AUTOSAR XML (schema 4-3-0)
package /ApplicationLayer/ApplicationPackage
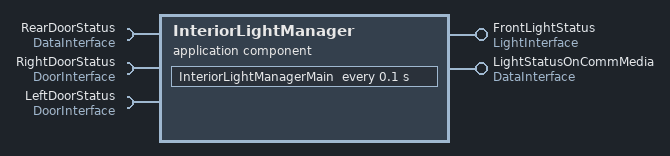
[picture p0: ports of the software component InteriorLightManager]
  application sw component type InteriorLightManager
    require port RearDoorStatus: required-interface=DataInterface
    require port RightDoorStatus: required-interface=DoorInterface
    require port LeftDoorStatus: required-interface=DoorInterface
    provide port FrontLightStatus: provided-interface=LightInterface
    provide port LightStatusOnCommMedia: provided-interface=DataInterface
    behavior InteriorLightManagerBehaviour: data-type-mapping=TypeMappings, handle-termination-and-restart=NO-SUPPORT
      timing event interiorLightManagerMainEvent: start-on-event=InteriorLightManagerMain, period=0.1
      runnable InteriorLightManagerMain: symbol=interiorLightManagerMain
        data-read-access:
          access dataReadAccess_InteriorLightManagerMain_RearDoorStatus_message: accessed-variable=RearDoorStatus.message
          access dataReadAccess_InteriorLightManagerMain_RightDoorStatus_status: accessed-variable=RightDoorStatus.status
          access dataReadAccess_InteriorLightManagerMain_LeftDoorStatus_status: accessed-variable=LeftDoorStatus.status
        data-write-access:
          access dataWriteAccess_InteriorLightManagerMain_FrontLightStatus_status: accessed-variable=FrontLightStatus.status
          access dataWriteAccess_InteriorLightManagerMain_LightStatusOnCommMedia_message: accessed-variable=LightStatusOnCommMedia.message
  swc implementation InteriorLightManagerImpl: programming-language=C, vendor-id=0, behavior=InteriorLightManagerBehaviour
    code-descriptors:
      code src: artifact-descriptors=autosar-engineering-object={short-label=artifactDescriptor, category=artifactDescriptorCategory}
    resource consumption resourceConsumption
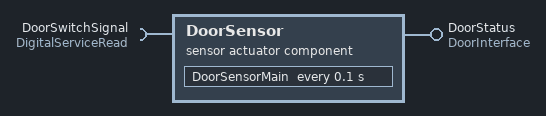
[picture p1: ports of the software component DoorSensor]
  sensor actuator sw component type DoorSensor
    require port DoorSwitchSignal: required-interface=DigitalServiceRead
    provide port DoorStatus: provided-interface=DoorInterface
    behavior DoorSensorBehavior: data-type-mapping=TypeMappings, handle-termination-and-restart=NO-SUPPORT, supports-multiple-instantiation=true
      timing event doorSensorMainEvent: start-on-event=DoorSensorMain, period=0.1
      runnable DoorSensorMain: symbol=doorSensorMain
        data-write-access:
          access dataWriteAccess_DoorSensorMain_DoorStatus_status: accessed-variable=DoorStatus.status
        sync call DoorSwitchSignal_Read: operation=DoorSwitchSignal.Read, timeout=0.0
  swc implementation DoorSensorImplementation: programming-language=C, vendor-id=0, behavior=DoorSensorBehavior
    code-descriptors:
      code src: artifact-descriptors=autosar-engineering-object={short-label=artifactDescriptor, category=artifactDescriptorCategory}
    resource consumption resourceConsumption
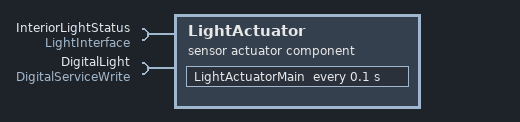
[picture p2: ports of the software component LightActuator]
  sensor actuator sw component type LightActuator
    require port InteriorLightStatus: required-interface=LightInterface
    require port DigitalLight: required-interface=DigitalServiceWrite
    behavior LightActuatorBehavior: data-type-mapping=TypeMappings, handle-termination-and-restart=NO-SUPPORT, supports-multiple-instantiation=true
      timing event lightActuatorMainEvent: start-on-event=LightActuatorMain, period=0.1
      runnable LightActuatorMain: symbol=lightActuatorMain
        data-read-access:
          access dataReadAccess_LightActuatorMain_InteriorLightStatus_status: accessed-variable=InteriorLightStatus.status
        sync call DigitalLight_Write: operation=DigitalLight.Write, timeout=0.0
  swc implementation LightActuatorImplementation: programming-language=C, vendor-id=0, behavior=LightActuatorBehavior
    code-descriptors:
      code src: artifact-descriptors=autosar-engineering-object={short-label=artifactDescriptor, category=artifactDescriptorCategory}
    resource consumption resourceConsumption
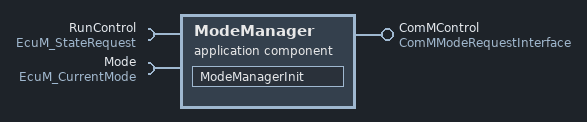
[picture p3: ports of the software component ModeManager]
  application sw component type ModeManager
    provide port ComMControl: provided-interface=ComMModeRequestInterface
    require port RunControl: required-interface=EcuM_StateRequest
    require port Mode: required-interface=EcuM_CurrentMode
    behavior ModeManagerBehavior: data-type-mapping=[EcuMFixedTypeMappings, TypeMappings], handle-termination-and-restart=NO-SUPPORT
      swc mode switch event modeManagerInitEvent: start-on-event=ModeManagerInit, activation=ON-EXIT, mode=Mode.currentMode.STARTUP
      runnable ModeManagerInit: symbol=modeManagerInit
        data-write-access:
          access dataWriteAccess_ModeManagerInit_ComMControl_requestedMode: accessed-variable=ComMControl.requestedMode
        sync call RunControl_RequestRUN: operation=RunControl.RequestRUN, timeout=0.0
  swc implementation ModeManagerImpl: programming-language=C, vendor-id=0, behavior=ModeManagerBehavior
    code-descriptors:
      code src: artifact-descriptors=autosar-engineering-object={short-label=artifactDescriptor, category=artifactDescriptorCategory}
    resource consumption resourceConsumption
package /ApplicationLayer/CompositionPackage
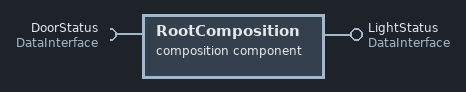
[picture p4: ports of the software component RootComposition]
  composition sw component type RootComposition
    provide port LightStatus: provided-interface=DataInterface
    require port DoorStatus: required-interface=DataInterface
    9 x component:
      frontLightActuator: type=LightActuator
      rightDoorSensor: type=DoorSensor
      leftDoorSensor: type=DoorSensor
      lightManager: type=InteriorLightManager
      modeManager: type=ModeManager
      ioHwAb: type=IoHwAb
      ecuM: type=EcuM
      bswM: type=BswM
      comM: type=ComM
    connect ioHwAb.Digital_FrontLight -> frontLightActuator.DigitalLight
    connect ioHwAb.Digital_FrontDoorRight -> rightDoorSensor.DoorSwitchSignal
    connect ioHwAb.Digital_FrontDoorLeft -> leftDoorSensor.DoorSwitchSignal
    connect lightManager.FrontLightStatus -> frontLightActuator.InteriorLightStatus
    connect rightDoorSensor.DoorStatus -> lightManager.RightDoorStatus
    connect leftDoorSensor.DoorStatus -> lightManager.LeftDoorStatus
    connect modeManager.ComMControl -> bswM.modeRequestPort_SwcStartCommunication
    connect ecuM.SR_User -> modeManager.RunControl
    connect ecuM.currentMode -> modeManager.Mode
    delegate lightManager.LightStatusOnCommMedia <-> outer port LightStatus
    delegate lightManager.RearDoorStatus <-> outer port DoorStatus
package /ApplicationLayer/Interface
  impl type LightStatusImpl: category=VALUE, base-type=uint32, compu {1=OFF, 2=ON}
  app type LightStatus: category=VALUE, compu {1=OFF, 2=ON}
  impl type DoorStatusImpl: category=BOOLEAN, base-type=boolean
  app type DoorStatus: category=BOOLEAN
  impl type IntImpl: category=VALUE, base-type=uint32
  app type Int: category=VALUE
  sender receiver interface LightInterface
    data status: type=LightStatus
  sender receiver interface DoorInterface
    data status: type=DoorStatus
  sender receiver interface DataInterface
    data message: type=Int
  data type mapping set TypeMappings
    data-type-maps:
      application-data-type=Int, implementation-data-type=IntImpl
      application-data-type=LightStatus, implementation-data-type=LightStatusImpl
      application-data-type=DoorStatus, implementation-data-type=DoorStatusImpl
package /ApplicationLayer/Signals
  pdu RxMessageiSignalPdu: unused-bit-pattern=0
    signal RxMessageiSignal: 0 bit, system signal RxMessageSystemSignal, data-type-policy=NETWORK-REPRESENTATION-FROM-COM-SPEC
  pdu TxMessageiSignalPdu: unused-bit-pattern=0
    signal TxMessageiSignal: 0 bit, system signal TxMessageSystemSignal, data-type-policy=NETWORK-REPRESENTATION-FROM-COM-SPEC
package /ApplicationLayer/EcuExtract
  system InteriorLightCANEcuExtract: category=ECU_EXTRACT, system-version=1
    system mapping ImplementationMappings
      sw-impl-mappings:
        9 x swc to impl mapping:
          IoHwAbMap: component-implementation=IoHwAbImpl, component=RootSwComposition.ioHwAb
          EcuMMap: component-implementation=EcuMFixedImpl, component=RootSwComposition.ecuM
          SwcToImplMapping_for_BswMComponentImpl_to_bswM: component-implementation=BswMComponentImpl, component=RootSwComposition.bswM
          SwcToImplMapping_for_ComMImpl_to_comM: component-implementation=ComMImpl, component=RootSwComposition.comM
          SwcToImplMapping_for_DoorSensorImplementation_to_leftDoorSensor: component-implementation=DoorSensorImplementation, component=RootSwComposition.leftDoorSensor
          SwcToImplMapping_for_DoorSensorImplementation_to_rightDoorSensor: component-implementation=DoorSensorImplementation, component=RootSwComposition.rightDoorSensor
          SwcToImplMapping_for_LightActuatorImplementation_to_frontLightActuator: component-implementation=LightActuatorImplementation, component=RootSwComposition.frontLightActuator
          SwcToImplMapping_for_ModeManagerImpl_to_modeManager: component-implementation=ModeManagerImpl, component=RootSwComposition.modeManager
          SwcToImplMapping_for_InteriorLightManagerImpl_to_lightManager: component-implementation=InteriorLightManagerImpl, component=RootSwComposition.lightManager
    system mapping SignalMappings
      data-mappings:
        data-element=RootSwComposition.LightStatus.message, system-signal=TxMessageSystemSignal
        data-element=RootSwComposition.DoorStatus.message, system-signal=RxMessageSystemSignal
    root-software-compositions:
      root sw composition prototype RootSwComposition: software-composition=RootComposition
package /BSWConfiguration/Services/Os
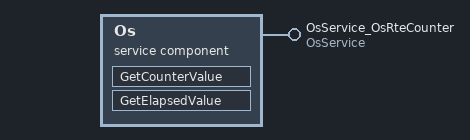
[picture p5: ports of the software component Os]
  service sw component type Os
    provide port OsService_OsRteCounter: provided-interface=OsService
    behavior OsBehavior: handle-termination-and-restart=NO-SUPPORT, port-api-option{port-defined-argument-value{value=CounterType:0, value-type=CounterType}, port=OsService_OsRteCounter}
      operation invoked event GetCounterValue_OsService_OsRteCounter_GetCounterValue: start-on-event=GetCounterValue, operation=OsService_OsRteCounter.GetCounterValue
      operation invoked event GetElapsedValue_OsService_OsRteCounter_GetElapsedValue: start-on-event=GetElapsedValue, operation=OsService_OsRteCounter.GetElapsedValue
      runnable GetCounterValue: symbol=Os_GetCounterValue
      runnable GetElapsedValue: symbol=Os_GetElapsedValue
  swc implementation OsImpl: programming-language=C, vendor-id=60, behavior=OsBehavior
    code-descriptors:
      code src: artifact-descriptors=autosar-engineering-object={short-label=artifactDescriptor, category=artifactDescriptorCategory}
    resource consumption resourceConsumption
package /BSWConfiguration/Services/BswM
  impl type ComMModeEnum: compu {0=COMM_NO_COMMUNICATION, 1=COMM_SILENT_COMMUNICATION, 2=COMM_FULL_COMMUNICATION}, implementation-data-type=uint8
  sender receiver interface ComMModeRequestInterface
    data requestedMode: type=ComMModeEnum
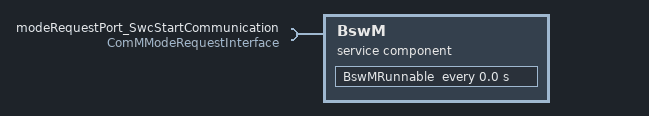
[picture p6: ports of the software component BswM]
  service sw component type BswM
    require port modeRequestPort_SwcStartCommunication: required-interface=ComMModeRequestInterface
    behavior BswMInternalBehavior: handle-termination-and-restart=NO-SUPPORT
      timing event BswMRunnableEvent: start-on-event=BswMRunnable, period=0.0
      runnable BswMRunnable: symbol=BswM_MainFunction
        data-receive-point-by-arguments:
          access dataReceivePoint_BswMRunnable_modeRequestPort_SwcStartCommunication_requestedMode: accessed-variable=modeRequestPort_SwcStartCommunication.requestedMode
  swc implementation BswMComponentImpl: programming-language=C, vendor-id=60, behavior=BswMInternalBehavior
    code-descriptors:
      code src: artifact-descriptors=autosar-engineering-object={short-label=artifactDescriptor, category=artifactDescriptorCategory}
    resource consumption resourceConsumption
package /BSWConfiguration/Services/ComM
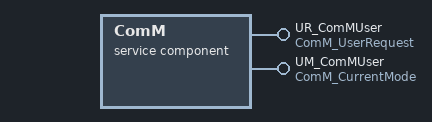
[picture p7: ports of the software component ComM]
  service sw component type ComM
    provide port UR_ComMUser: provided-interface=ComM_UserRequest
    provide port UM_ComMUser: provided-interface=ComM_CurrentMode
    behavior ComMBehavior: data-type-mapping=ComMTypeMappings, handle-termination-and-restart=NO-SUPPORT, port-api-option{port-defined-argument-value{value=ComM_UserHandleType:0, value-type=ComM_UserHandleType}, port=UR_ComMUser}
      4 x operation invoked event:
        RequestComMode_UR_ComMUser_RequestComMode: start-on-event=RequestComMode, operation=UR_ComMUser.RequestComMode
        GetMaxComMode_UR_ComMUser_GetMaxComMode: start-on-event=GetMaxComMode, operation=UR_ComMUser.GetMaxComMode
        GetRequestedComMode_UR_ComMUser_GetRequestedComMode: start-on-event=GetRequestedComMode, operation=UR_ComMUser.GetRequestedComMode
        GetCurrentComMode_UR_ComMUser_GetCurrentComMode: start-on-event=GetCurrentComMode, operation=UR_ComMUser.GetCurrentComMode
      5 x runnable:
        ComM_MainFunction
          mode switch point modeSwitchPoint_ComM_MainFunction_UM_ComMUser_currentMode: mode-group=UM_ComMUser.currentMode
        RequestComMode: can-be-invoked-concurrently=true, symbol=ComM_RequestComMode
        GetMaxComMode: can-be-invoked-concurrently=true, symbol=ComM_GetMaxComMode
        GetRequestedComMode: can-be-invoked-concurrently=true, symbol=ComM_GetRequestedComMode
        GetCurrentComMode: can-be-invoked-concurrently=true, symbol=ComM_GetCurrentComMode
  swc implementation ComMImpl: programming-language=C, vendor-id=60, behavior=ComMBehavior
    code-descriptors:
      code src: artifact-descriptors=autosar-engineering-object={short-label=artifactDescriptor, category=artifactDescriptorCategory}
    resource consumption resourceConsumption
package /BSWConfiguration/Services/IoHwAb
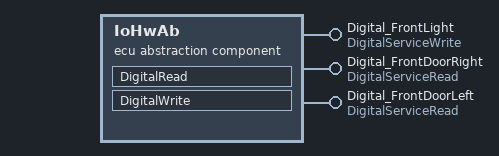
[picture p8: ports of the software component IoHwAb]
  ecu abstraction sw component type IoHwAb
    provide port Digital_FrontLight: provided-interface=DigitalServiceWrite
    provide port Digital_FrontDoorRight: provided-interface=DigitalServiceRead
    provide port Digital_FrontDoorLeft: provided-interface=DigitalServiceRead
    behavior IoHwAbBehavior: handle-termination-and-restart=NO-SUPPORT
      operation invoked event DigitalRead_Digital_FrontDoorRight_Read: start-on-event=DigitalRead, operation=Digital_FrontDoorRight.Read
      operation invoked event DigitalRead_Digital_FrontDoorLeft_Read: start-on-event=DigitalRead, operation=Digital_FrontDoorLeft.Read
      operation invoked event DigitalWrite_Digital_FrontLight_Write: start-on-event=DigitalWrite, operation=Digital_FrontLight.Write
      port-api-options:
        {port-defined-argument-value{value=IoHwAb_SignalType_:0, value-type=IoHwAb_SignalType_}, port=Digital_FrontLight}
        {port-defined-argument-value{value=IoHwAb_SignalType_:1, value-type=IoHwAb_SignalType_}, port=Digital_FrontDoorRight}
        {port-defined-argument-value{value=IoHwAb_SignalType_:2, value-type=IoHwAb_SignalType_}, port=Digital_FrontDoorLeft}
      runnable DigitalRead: can-be-invoked-concurrently=true, symbol=IoHwAb_Digital_Read
      runnable DigitalWrite: can-be-invoked-concurrently=true, symbol=IoHwAb_Digital_Write
  swc implementation IoHwAbImpl: programming-language=C, vendor-id=60, behavior=IoHwAbBehavior
    code-descriptors:
      code src: artifact-descriptors=autosar-engineering-object={short-label=artifactDescriptor, category=artifactDescriptorCategory}
    resource consumption resourceConsumption
package /BSWConfiguration/Services/Det
  service sw component type Det
    behavior DetBehavior: handle-termination-and-restart=NO-SUPPORT
      runnable ReportError: symbol=Det_ReportError
  swc implementation DetImpl: programming-language=C, vendor-id=60, behavior=DetBehavior
    code-descriptors:
      code src: artifact-descriptors=autosar-engineering-object={short-label=artifactDescriptor, category=artifactDescriptorCategory}
    resource consumption resourceConsumption
package /BSWConfiguration/Services/EcuM
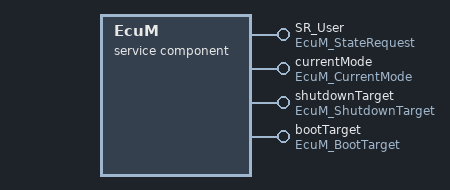
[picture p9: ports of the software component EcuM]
  service sw component type EcuM
    4 x provide port:
      SR_User: provided-interface=EcuM_StateRequest
      currentMode: provided-interface=EcuM_CurrentMode
      shutdownTarget: provided-interface=EcuM_ShutdownTarget
      bootTarget: provided-interface=EcuM_BootTarget
    behavior EcuMFixedBehavior: data-type-mapping=EcuMFixedTypeMappings, handle-termination-and-restart=NO-SUPPORT, port-api-option{port-defined-argument-value{value=EcuM_UserType:0, value-type=EcuM_UserType}, port=SR_User}
      9 x operation invoked event:
        RequestRUN_SR_User_RequestRUN: start-on-event=RequestRUN, operation=SR_User.RequestRUN
        ReleaseRUN_SR_User_ReleaseRUN: start-on-event=ReleaseRUN, operation=SR_User.ReleaseRUN
        RequestPOSTRUN_SR_User_RequestPOSTRUN: start-on-event=RequestPOSTRUN, operation=SR_User.RequestPOSTRUN
        ReleasePOSTRUN_SR_User_ReleasePOSTRUN: start-on-event=ReleasePOSTRUN, operation=SR_User.ReleasePOSTRUN
        SelectShutdownTarget_shutdownTarget_SelectShutdownTarget: start-on-event=SelectShutdownTarget, operation=shutdownTarget.SelectShutdownTarget
        GetShutdownTarget_shutdownTarget_GetShutdownTarget: start-on-event=GetShutdownTarget, operation=shutdownTarget.GetShutdownTarget
        GetLastShutdownTarget_shutdownTarget_GetLastShutdownTarget: start-on-event=GetLastShutdownTarget, operation=shutdownTarget.GetLastShutdownTarget
        SelectBootTarget_bootTarget_SelectBootTarget: start-on-event=SelectBootTarget, operation=bootTarget.SelectBootTarget
        GetBootTarget_bootTarget_GetBootTarget: start-on-event=GetBootTarget, operation=bootTarget.GetBootTarget
      10 x runnable:
        EcuM_MainFunction
          mode switch point modeSwitchPoint_EcuM_MainFunction_currentMode_currentMode: mode-group=currentMode.currentMode
        RequestRUN: can-be-invoked-concurrently=true, symbol=EcuM_RequestRUN
        ReleaseRUN: can-be-invoked-concurrently=true, symbol=EcuM_ReleaseRUN
        RequestPOSTRUN: can-be-invoked-concurrently=true, symbol=EcuM_RequestPOST_RUN
        ReleasePOSTRUN: can-be-invoked-concurrently=true, symbol=EcuM_ReleasePOST_RUN
        SelectShutdownTarget: can-be-invoked-concurrently=true, symbol=EcuM_SelectShutdownTarget
        GetShutdownTarget: can-be-invoked-concurrently=true, symbol=EcuM_GetShutdownTarget
        GetLastShutdownTarget: can-be-invoked-concurrently=true, symbol=EcuM_GetLastShutdownTarget
        SelectBootTarget: can-be-invoked-concurrently=true, symbol=EcuM_SelectBootTarget
        GetBootTarget: can-be-invoked-concurrently=true, symbol=EcuM_GetBootTarget
  swc implementation EcuMFixedImpl: programming-language=C, vendor-id=60, behavior=EcuMFixedBehavior
    code-descriptors:
      code src: artifact-descriptors=autosar-engineering-object={short-label=artifactDescriptor, category=artifactDescriptorCategory}
    resource consumption resourceConsumption
